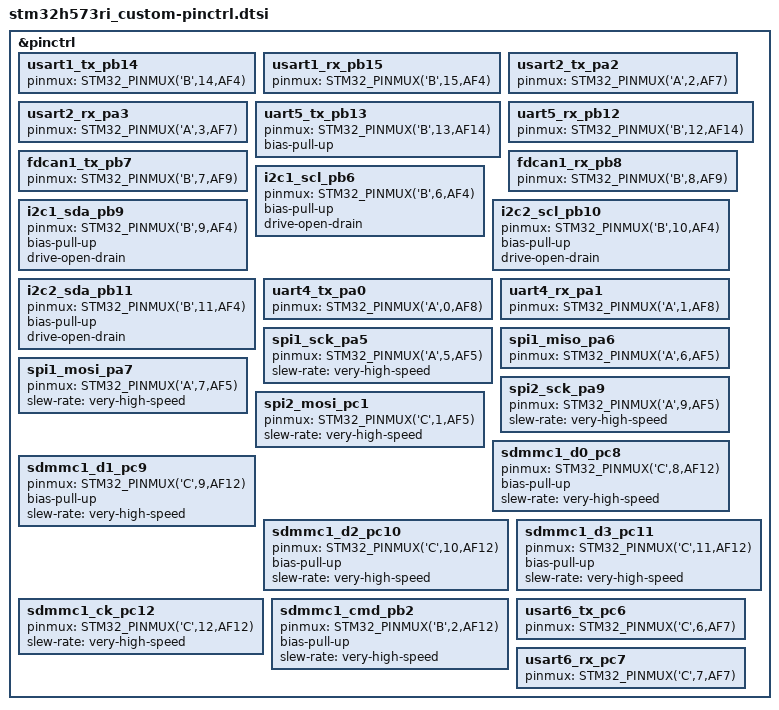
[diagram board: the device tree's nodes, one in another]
#include <dt-bindings/pinctrl/stm32-pinctrl.h>
&pinctrl {
        usart1_tx_pb14: usart1_tx_pb14 {
                pinmux = <STM32_PINMUX('B',14,AF4)>; };

        usart1_rx_pb15: usart1_rx_pb15 {
                pinmux = <STM32_PINMUX('B',15,AF4)>; };

        usart2_tx_pa2: usart2_tx_pa2 {
                pinmux = <STM32_PINMUX('A',2,AF7)>; };

        usart2_rx_pa3: usart2_rx_pa3 {
                pinmux = <STM32_PINMUX('A',3,AF7)>; };

        uart5_tx_pb13: uart5_tx_pb13 {
                pinmux = <STM32_PINMUX('B',13,AF14)>;
                bias-pull-up; };

        uart5_rx_pb12: uart5_rx_pb12 {
                pinmux = <STM32_PINMUX('B',12,AF14)>; };

        fdcan1_tx_pb7: fdcan1_tx_pb7 {
                pinmux = <STM32_PINMUX('B',7,AF9)>; };

        fdcan1_rx_pb8: fdcan1_rx_pb8 {
                pinmux = <STM32_PINMUX('B',8,AF9)>; };

        i2c1_scl_pb6: i2c1_scl_pb6 {
                pinmux = <STM32_PINMUX('B',6,AF4)>;
                bias-pull-up;
                drive-open-drain; };

        i2c1_sda_pb9: i2c1_sda_pb9 {
                pinmux = <STM32_PINMUX('B',9,AF4)>;
                bias-pull-up;
                drive-open-drain; };

        i2c2_scl_pb10: i2c2_scl_pb10 {
                pinmux = <STM32_PINMUX('B',10,AF4)>;
                bias-pull-up;
                drive-open-drain; };

        i2c2_sda_pb11: i2c2_sda_pb11 {
                pinmux = <STM32_PINMUX('B',11,AF4)>;
                bias-pull-up;
                drive-open-drain; };

        uart4_tx_pa0: uart4_tx_pa0 {
                pinmux = <STM32_PINMUX('A',0,AF8)>; };

        uart4_rx_pa1: uart4_rx_pa1 {
                pinmux = <STM32_PINMUX('A',1,AF8)>; };

        spi1_sck_pa5: spi1_sck_pa5 {
                pinmux = <STM32_PINMUX('A',5,AF5)>;
                slew-rate = "very-high-speed"; };

        spi1_miso_pa6: spi1_miso_pa6 {
                pinmux = <STM32_PINMUX('A',6,AF5)>; };

        spi1_mosi_pa7: spi1_mosi_pa7 {
                pinmux = <STM32_PINMUX('A',7,AF5)>;
                slew-rate = "very-high-speed"; };

        spi2_sck_pa9: spi2_sck_pa9 {
                pinmux = <STM32_PINMUX('A',9,AF5)>;
                slew-rate = "very-high-speed"; };

        spi2_mosi_pc1: spi2_mosi_pc1 {
                pinmux = <STM32_PINMUX('C',1,AF5)>;
                slew-rate = "very-high-speed"; };

        sdmmc1_d0_pc8: sdmmc1_d0_pc8 {
                pinmux = <STM32_PINMUX('C',8,AF12)>;
                bias-pull-up;
                slew-rate = "very-high-speed"; };

        sdmmc1_d1_pc9: sdmmc1_d1_pc9 {
                pinmux = <STM32_PINMUX('C',9,AF12)>;
                bias-pull-up;
                slew-rate = "very-high-speed"; };

        sdmmc1_d2_pc10: sdmmc1_d2_pc10 {
                pinmux = <STM32_PINMUX('C',10,AF12)>;
                bias-pull-up;
                slew-rate = "very-high-speed"; };

        sdmmc1_d3_pc11: sdmmc1_d3_pc11 {
                pinmux = <STM32_PINMUX('C',11,AF12)>;
                bias-pull-up;
                slew-rate = "very-high-speed"; };

        sdmmc1_ck_pc12: sdmmc1_ck_pc12 {
                pinmux = <STM32_PINMUX('C',12,AF12)>;
                slew-rate = "very-high-speed"; };

        sdmmc1_cmd_pb2: sdmmc1_cmd_pb2 {
                pinmux = <STM32_PINMUX('B',2,AF12)>;
                bias-pull-up;
                slew-rate = "very-high-speed"; };

        usart6_tx_pc6: usart6_tx_pc6 {
                pinmux = <STM32_PINMUX('C',6,AF7)>; };

        usart6_rx_pc7: usart6_rx_pc7 {
                pinmux = <STM32_PINMUX('C',7,AF7)>; };
};
